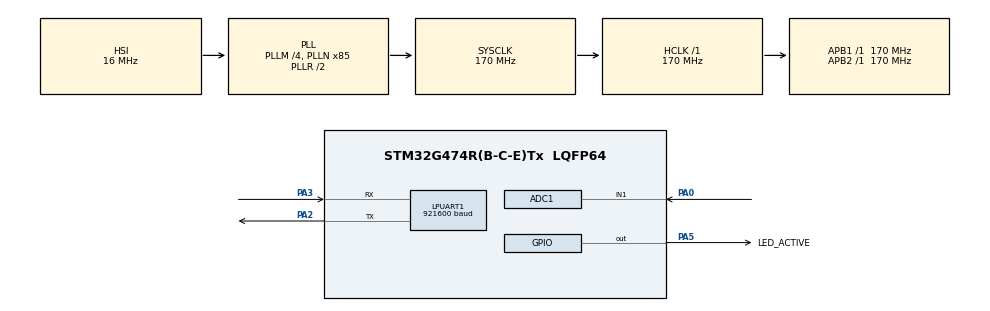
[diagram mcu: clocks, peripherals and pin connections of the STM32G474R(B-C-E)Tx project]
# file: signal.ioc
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ADC1.Channel-0\#ChannelRegularConversion=ADC_CHANNEL_1
ADC1.ClockPrescaler=ADC_CLOCK_SYNC_PCLK_DIV4
ADC1.DMAContinuousRequests=ENABLE
ADC1.ExternalTrigConv=ADC_EXTERNALTRIG_T3_TRGO
ADC1.NbrOfConversionFlag=1
ADC1.OffsetNumber-0\#ChannelRegularConversion=ADC_OFFSET_NONE
ADC1.OversamplingMode=ENABLE
ADC1.Rank-0\#ChannelRegularConversion=1
ADC1.Ratio=ADC_OVERSAMPLING_RATIO_16
ADC1.RightBitShift=ADC_RIGHTBITSHIFT_1
ADC1.SamplingTime-0\#ChannelRegularConversion=ADC_SAMPLETIME_24CYCLES_5
ADC1.master=1
Dma.ADC1.0.Direction=DMA_PERIPH_TO_MEMORY
Dma.ADC1.0.EventEnable=DISABLE
Dma.ADC1.0.Instance=DMA1_Channel1
Dma.ADC1.0.MemDataAlignment=DMA_MDATAALIGN_HALFWORD
Dma.ADC1.0.MemInc=DMA_MINC_ENABLE
Dma.ADC1.0.Mode=DMA_CIRCULAR
Dma.ADC1.0.PeriphDataAlignment=DMA_PDATAALIGN_HALFWORD
Dma.ADC1.0.PeriphInc=DMA_PINC_DISABLE
Dma.ADC1.0.Polarity=HAL_DMAMUX_REQ_GEN_RISING
Dma.ADC1.0.Priority=DMA_PRIORITY_VERY_HIGH
Dma.ADC1.0.RequestNumber=1
Dma.ADC1.0.SignalID=NONE
Dma.ADC1.0.SyncEnable=DISABLE
Dma.ADC1.0.SyncPolarity=HAL_DMAMUX_SYNC_NO_EVENT
Dma.ADC1.0.SyncRequestNumber=1
Dma.ADC1.0.SyncSignalID=NONE
Dma.FMAC_READ.2.Direction=DMA_PERIPH_TO_MEMORY
Dma.FMAC_READ.2.EventEnable=DISABLE
Dma.FMAC_READ.2.Instance=DMA1_Channel3
Dma.FMAC_READ.2.MemDataAlignment=DMA_MDATAALIGN_HALFWORD
Dma.FMAC_READ.2.MemInc=DMA_MINC_ENABLE
Dma.FMAC_READ.2.Mode=DMA_CIRCULAR
Dma.FMAC_READ.2.PeriphDataAlignment=DMA_PDATAALIGN_WORD
Dma.FMAC_READ.2.PeriphInc=DMA_PINC_DISABLE
Dma.FMAC_READ.2.Polarity=HAL_DMAMUX_REQ_GEN_RISING
Dma.FMAC_READ.2.Priority=DMA_PRIORITY_HIGH
Dma.FMAC_READ.2.RequestNumber=1
Dma.FMAC_READ.2.SignalID=NONE
Dma.FMAC_READ.2.SyncEnable=DISABLE
Dma.FMAC_READ.2.SyncPolarity=HAL_DMAMUX_SYNC_NO_EVENT
Dma.FMAC_READ.2.SyncRequestNumber=1
Dma.FMAC_READ.2.SyncSignalID=NONE
Dma.FMAC_WRITE.1.Direction=DMA_MEMORY_TO_PERIPH
Dma.FMAC_WRITE.1.EventEnable=DISABLE
Dma.FMAC_WRITE.1.Instance=DMA1_Channel2
Dma.FMAC_WRITE.1.MemDataAlignment=DMA_MDATAALIGN_HALFWORD
Dma.FMAC_WRITE.1.MemInc=DMA_MINC_ENABLE
Dma.FMAC_WRITE.1.Mode=DMA_CIRCULAR
Dma.FMAC_WRITE.1.PeriphDataAlignment=DMA_PDATAALIGN_WORD
Dma.FMAC_WRITE.1.PeriphInc=DMA_PINC_DISABLE
Dma.FMAC_WRITE.1.Polarity=HAL_DMAMUX_REQ_GEN_RISING
Dma.FMAC_WRITE.1.Priority=DMA_PRIORITY_HIGH
Dma.FMAC_WRITE.1.RequestNumber=1
Dma.FMAC_WRITE.1.SignalID=NONE
Dma.FMAC_WRITE.1.SyncEnable=DISABLE
Dma.FMAC_WRITE.1.SyncPolarity=HAL_DMAMUX_SYNC_NO_EVENT
Dma.FMAC_WRITE.1.SyncRequestNumber=1
Dma.FMAC_WRITE.1.SyncSignalID=NONE
Dma.LPUART1_TX.3.Direction=DMA_MEMORY_TO_PERIPH
Dma.LPUART1_TX.3.EventEnable=DISABLE
Dma.LPUART1_TX.3.Instance=DMA1_Channel4
Dma.LPUART1_TX.3.MemDataAlignment=DMA_MDATAALIGN_BYTE
Dma.LPUART1_TX.3.MemInc=DMA_MINC_ENABLE
Dma.LPUART1_TX.3.Mode=DMA_NORMAL
Dma.LPUART1_TX.3.PeriphDataAlignment=DMA_PDATAALIGN_BYTE
Dma.LPUART1_TX.3.PeriphInc=DMA_PINC_DISABLE
Dma.LPUART1_TX.3.Polarity=HAL_DMAMUX_REQ_GEN_RISING
Dma.LPUART1_TX.3.Priority=DMA_PRIORITY_LOW
Dma.LPUART1_TX.3.RequestNumber=1
Dma.LPUART1_TX.3.SignalID=NONE
Dma.LPUART1_TX.3.SyncEnable=DISABLE
Dma.LPUART1_TX.3.SyncPolarity=HAL_DMAMUX_SYNC_NO_EVENT
Dma.LPUART1_TX.3.SyncRequestNumber=1
Dma.LPUART1_TX.3.SyncSignalID=NONE
Dma.Request0=ADC1
Dma.Request1=FMAC_WRITE
Dma.Request2=FMAC_READ
Dma.Request3=LPUART1_TX
FREERTOS.Tasks01=DetectorTask,40,512,StartDetectorTask,Default,NULL,Dynamic,NULL,NULL;TelemetryTask,24,256,StartTelemetryTask,Default,NULL,Dynamic,NULL,NULL
FREERTOS.configTOTAL_HEAP_SIZE=10240
FREERTOS.configUSE_NEWLIB_REENTRANT=1
LPUART1.BaudRate=921600
Mcu.Family=STM32G4
Mcu.Name=STM32G474R(B-C-E)Tx
Mcu.Package=LQFP64
NVIC.ADC1_2_IRQn=true\:5\:0\:false\:false\:true\:true\:true\:true\:true
NVIC.DMA1_Channel1_IRQn=true\:5\:0\:false\:false\:true\:true\:false\:true\:true
NVIC.DMA1_Channel2_IRQn=true\:5\:0\:false\:false\:true\:true\:false\:true\:true
NVIC.DMA1_Channel3_IRQn=true\:5\:0\:false\:false\:true\:true\:false\:true\:true
NVIC.DMA1_Channel4_IRQn=true\:5\:0\:false\:false\:true\:true\:false\:true\:true
NVIC.FMAC_IRQn=true\:5\:0\:false\:false\:true\:true\:true\:true\:true
NVIC.LPUART1_IRQn=true\:5\:0\:false\:false\:true\:true\:false\:true\:true
NVIC.PriorityGroup=NVIC_PRIORITYGROUP_4
NVIC.TIM6_DAC_IRQn=true\:15\:0\:false\:false\:true\:false\:false\:true\:true
NVIC.TimeBase=TIM6_DAC_IRQn
NVIC.TimeBaseIP=TIM6
PA0.Mode=IN1-Single-Ended
PA0.Signal=ADC1_IN1
PA13.Mode=Serial_Wire
PA13.Signal=SYS_JTMS-SWDIO
PA14.Mode=Serial_Wire
PA14.Signal=SYS_JTCK-SWCLK
PA2.Mode=Asynchronous
PA2.Signal=LPUART1_TX
PA3.Mode=Asynchronous
PA3.Signal=LPUART1_RX
PA5.GPIO_Label=LED_ACTIVE
PA5.Signal=GPIO_Output
ProjectManager.HeapSize=0x200
ProjectManager.StackSize=0x400
ProjectManager.TargetToolchain=STM32CubeIDE
RCC.ADC12Freq_Value=170000000
RCC.ADC345Freq_Value=170000000
RCC.AHBFreq_Value=170000000
RCC.APB1Freq_Value=170000000
RCC.APB1TimFreq_Value=170000000
RCC.APB2Freq_Value=170000000
RCC.APB2TimFreq_Value=170000000
RCC.CortexFreq_Value=170000000
RCC.EXTERNAL_CLOCK_VALUE=12288000
RCC.HCLKFreq_Value=170000000
RCC.HSE_VALUE=8000000
RCC.HSI48_VALUE=48000000
RCC.HSI_VALUE=16000000
RCC.LSE_VALUE=32768
RCC.PLLM=RCC_PLLM_DIV4
RCC.PLLN=85
RCC.SYSCLKFreq_VALUE=170000000
RCC.SYSCLKSource=RCC_SYSCLKSOURCE_PLLCLK
RCC.USBFreq_Value=170000000
RCC.VCOOutputFreq_Value=340000000
TIM3.PeriodNoDither=99
TIM3.Prescaler=169
TIM3.TIM_MasterOutputTrigger=TIM_TRGO_UPDATE
VP_FMAC_VS_FMAC.Mode=FMAC_Activate
VP_FREERTOS_VS_CMSIS_V2.Mode=CMSIS_V2
VP_SYS_VS_DBSignals.Mode=DisableDeadBatterySignals
VP_SYS_VS_tim6.Mode=TIM6
VP_TIM3_VS_ClockSourceINT.Mode=Internal
board=custom

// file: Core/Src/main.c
/* USER CODE BEGIN Header */
/**
  ******************************************************************************
  * @file           : main.c
  * @brief          : Main program body
  ******************************************************************************
  * @attention
  *
  * Copyright (c) 2026 STMicroelectronics.
  * All rights reserved.
  *
  * This software is licensed under terms that can be found in the LICENSE file
  * in the root directory of this software component.
  * If no LICENSE file comes with this software, it is provided AS-IS.
  *
  ******************************************************************************
  */
/* USER CODE END Header */
#include "main.h"
#include "cmsis_os.h"
#include "adc.h"
#include "dma.h"
#include "fmac.h"
#include "usart.h"
#include "tim.h"
#include "gpio.h"

void SystemClock_Config(void);
void MX_FREERTOS_Init(void);

int main(void)
{

  /* MCU Configuration--------------------------------------------------------*/

  /* Reset of all peripherals, Initializes the Flash interface and the Systick. */
  HAL_Init();

  /* Configure the system clock */
  SystemClock_Config();

  /* Initialize all configured peripherals */
  MX_GPIO_Init();
  MX_DMA_Init();
  MX_ADC1_Init();
  MX_TIM3_Init();
  MX_FMAC_Init();
  MX_LPUART1_UART_Init();

  /* Init scheduler */
  osKernelInitialize();  /* Call init function for freertos objects (in cmsis_os2.c) */
  MX_FREERTOS_Init();

  /* Start scheduler */
  osKernelStart();

  /* We should never get here as control is now taken by the scheduler */

  /* Infinite loop */
  while (1)
  {

  }
}

void SystemClock_Config(void)
{
  RCC_OscInitTypeDef RCC_OscInitStruct = {0};
  RCC_ClkInitTypeDef RCC_ClkInitStruct = {0};

  /** Configure the main internal regulator output voltage
  */
  HAL_PWREx_ControlVoltageScaling(PWR_REGULATOR_VOLTAGE_SCALE1_BOOST);

  /** Initializes the RCC Oscillators according to the specified parameters
  * in the RCC_OscInitTypeDef structure.
  */
  RCC_OscInitStruct.OscillatorType = RCC_OSCILLATORTYPE_HSI;
  RCC_OscInitStruct.HSIState = RCC_HSI_ON;
  RCC_OscInitStruct.HSICalibrationValue = RCC_HSICALIBRATION_DEFAULT;
  RCC_OscInitStruct.PLL.PLLState = RCC_PLL_ON;
  RCC_OscInitStruct.PLL.PLLSource = RCC_PLLSOURCE_HSI;
  RCC_OscInitStruct.PLL.PLLM = RCC_PLLM_DIV4;
  RCC_OscInitStruct.PLL.PLLN = 85;
  RCC_OscInitStruct.PLL.PLLP = RCC_PLLP_DIV2;
  RCC_OscInitStruct.PLL.PLLQ = RCC_PLLQ_DIV2;
  RCC_OscInitStruct.PLL.PLLR = RCC_PLLR_DIV2;
  if (HAL_RCC_OscConfig(&RCC_OscInitStruct) != HAL_OK)
  {
    Error_Handler();
  }

  /** Initializes the CPU, AHB and APB buses clocks
  */
  RCC_ClkInitStruct.ClockType = RCC_CLOCKTYPE_HCLK|RCC_CLOCKTYPE_SYSCLK
                              |RCC_CLOCKTYPE_PCLK1|RCC_CLOCKTYPE_PCLK2;
  RCC_ClkInitStruct.SYSCLKSource = RCC_SYSCLKSOURCE_PLLCLK;
  RCC_ClkInitStruct.AHBCLKDivider = RCC_SYSCLK_DIV1;
  RCC_ClkInitStruct.APB1CLKDivider = RCC_HCLK_DIV1;
  RCC_ClkInitStruct.APB2CLKDivider = RCC_HCLK_DIV1;

  if (HAL_RCC_ClockConfig(&RCC_ClkInitStruct, FLASH_LATENCY_4) != HAL_OK)
  {
    Error_Handler();
  }
}

void HAL_TIM_PeriodElapsedCallback(TIM_HandleTypeDef *htim)
{
  if (htim->Instance == TIM6)
  {
    HAL_IncTick();
  }
}

void Error_Handler(void)
{
  __disable_irq();
  while (1)
  {
  }
}

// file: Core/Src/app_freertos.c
/* USER CODE BEGIN Header */
/**
  ******************************************************************************
  * File Name          : app_freertos.c
  * Description        : Code for freertos applications
  ******************************************************************************
  * @attention
  *
  * Copyright (c) 2026 STMicroelectronics.
  * All rights reserved.
  *
  * This software is licensed under terms that can be found in the LICENSE file
  * in the root directory of this software component.
  * If no LICENSE file comes with this software, it is provided AS-IS.
  *
  ******************************************************************************
  */
/* USER CODE END Header */

#include "FreeRTOS.h"
#include "task.h"
#include "main.h"
#include "cmsis_os.h"

/* USER CODE BEGIN Includes */
#include "detector_app.h"
/* USER CODE END Includes */

/* Definitions for DetectorTask */
osThreadId_t DetectorTaskHandle;
const osThreadAttr_t DetectorTask_attributes = {
  .name = "DetectorTask",
  .priority = (osPriority_t) osPriorityHigh,
  .stack_size = 512 * 4
};
/* Definitions for TelemetryTask */
osThreadId_t TelemetryTaskHandle;
const osThreadAttr_t TelemetryTask_attributes = {
  .name = "TelemetryTask",
  .priority = (osPriority_t) osPriorityNormal,
  .stack_size = 256 * 4
};

void StartDetectorTask(void *argument);
void StartTelemetryTask(void *argument);

void MX_FREERTOS_Init(void); /* (MISRA C 2004 rule 8.1) */

void MX_FREERTOS_Init(void) {

  /* USER CODE BEGIN RTOS_QUEUES */
  DetectorApp_CreateQueues();
  /* USER CODE END RTOS_QUEUES */

  /* Create the thread(s) */
  /* creation of DetectorTask */
  DetectorTaskHandle = osThreadNew(StartDetectorTask, NULL, &DetectorTask_attributes);

  /* creation of TelemetryTask */
  TelemetryTaskHandle = osThreadNew(StartTelemetryTask, NULL, &TelemetryTask_attributes);

}

void StartDetectorTask(void *argument)
{
  /* USER CODE BEGIN StartDetectorTask */
  DetectorApp_DetectorTask(argument);
  /* USER CODE END StartDetectorTask */
}

void StartTelemetryTask(void *argument)
{
  /* USER CODE BEGIN StartTelemetryTask */
  DetectorApp_TelemetryTask(argument);
  /* USER CODE END StartTelemetryTask */
}
